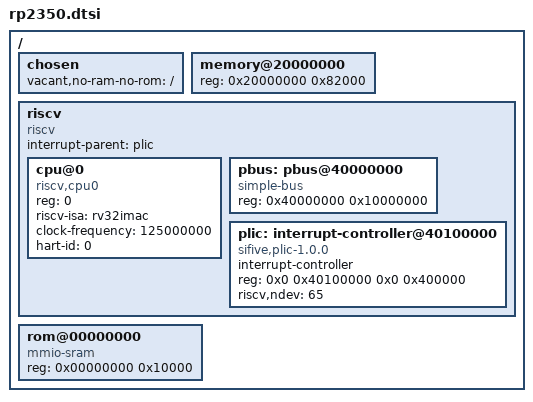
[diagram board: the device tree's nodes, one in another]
/*
 * Copyright (c) 2026 SUZINEE
 * SPDX-License-Identifier: Apache-2.0
 */

#include <dt-bindings/memory/riscv-mmu.h>
#include <dt-bindings/zephyr/zephyr-riscv-ext.h>

/ {
	#address-cells = <1>;
	#size-cells = <1>;

	chosen {
		vacant,no-ram-no-rom = "/";
	};

	memory@20000000 {
		device_type = "memory";
		reg = <0x20000000 0x82000>; // 520 KB SRAM
	};

	riscv {
		#address-cells = <1>;
		#size-cells = <1>;
		compatible = "riscv";
		interrupt-parent = <&plic>;

		cpu@0 {
			compatible = "riscv,cpu0";
			device_type = "cpu";
			reg = <0>;
			riscv-isa = "rv32imac";
			clock-frequency = <125000000>;

			/* RISC-V hart ID */
			hart-id = <0>;
		};

		pbus: pbus@40000000 {
			compatible = "simple-bus";
			#address-cells = <1>;
			#size-cells = <1>;
			reg = <0x40000000 0x10000000>; // APB base, placeholder size
			/* More peripherals will be added here */
		};

		plic: interrupt-controller@40100000 {
			compatible = "sifive,plic-1.0.0", "riscv,plic0";
			#interrupt-cells = <3>;
			interrupt-controller;
			reg = <0x0 0x40100000 0x0 0x400000>;
			riscv,ndev = <65>;
		};
	};

	// BootROM definition
	rom@00000000 {
		compatible = "mmio-sram";
		reg = <0x00000000 0x10000>; // 64 KB BootROM
		status = "okay";
	};
};
